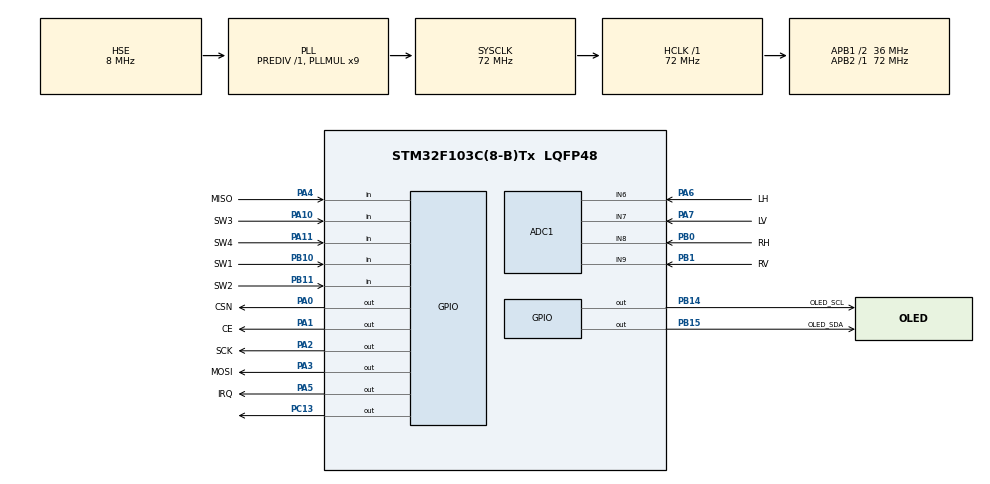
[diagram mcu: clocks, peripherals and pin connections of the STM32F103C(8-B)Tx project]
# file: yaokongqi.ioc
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ADC1.Channel-0\#ChannelRegularConversion=ADC_CHANNEL_6
ADC1.NbrOfConversionFlag=1
ADC1.Rank-0\#ChannelRegularConversion=1
ADC1.SamplingTime-0\#ChannelRegularConversion=ADC_SAMPLETIME_1CYCLE_5
ADC1.master=1
FREERTOS.Tasks01=defaultTask,24,128,StartDefaultTask,Default,NULL,Dynamic,NULL,NULL
FREERTOS.configTOTAL_HEAP_SIZE=8000
Mcu.Family=STM32F1
Mcu.Name=STM32F103C(8-B)Tx
Mcu.Package=LQFP48
NVIC.PriorityGroup=NVIC_PRIORITYGROUP_4
NVIC.TIM3_IRQn=true\:15\:0\:false\:false\:true\:false\:false\:true\:true
NVIC.TimeBase=TIM3_IRQn
NVIC.TimeBaseIP=TIM3
PA0-WKUP.GPIO_Label=CSN
PA0-WKUP.GPIO_PuPd=GPIO_NOPULL
PA0-WKUP.PinState=GPIO_PIN_SET
PA0-WKUP.Signal=GPIO_Output
PA1.GPIO_Label=CE
PA1.Signal=GPIO_Output
PA10.GPIO_Label=SW3
PA10.Signal=GPIO_Input
PA11.GPIO_Label=SW4
PA11.Signal=GPIO_Input
PA13.Mode=Serial_Wire
PA13.Signal=SYS_JTMS-SWDIO
PA14.Mode=Serial_Wire
PA14.Signal=SYS_JTCK-SWCLK
PA2.GPIO_Label=SCK
PA2.Signal=GPIO_Output
PA3.GPIO_Label=MOSI
PA3.Signal=GPIO_Output
PA4.GPIO_Label=MISO
PA4.GPIO_PuPd=GPIO_PULLUP
PA4.Signal=GPIO_Input
PA5.GPIO_Label=IRQ
PA5.Signal=GPIO_Output
PA6.GPIO_Label=LH
PA6.Signal=ADCx_IN6
PA7.GPIO_Label=LV
PA7.Signal=ADCx_IN7
PB0.GPIO_Label=RH
PB0.Signal=ADCx_IN8
PB1.GPIO_Label=RV
PB1.Signal=ADCx_IN9
PB10.GPIO_Label=SW1
PB10.Signal=GPIO_Input
PB11.GPIO_Label=SW2
PB11.Signal=GPIO_Input
PB14.GPIO_Label=OLED_SCL
PB14.Signal=GPIO_Output
PB15.GPIO_Label=OLED_SDA
PB15.Signal=GPIO_Output
PC13-TAMPER-RTC.Signal=GPIO_Output
PD0-OSC_IN.Mode=HSE-External-Oscillator
PD0-OSC_IN.Signal=RCC_OSC_IN
PD1-OSC_OUT.Mode=HSE-External-Oscillator
PD1-OSC_OUT.Signal=RCC_OSC_OUT
ProjectManager.HeapSize=0x200
ProjectManager.StackSize=0x400
ProjectManager.TargetToolchain=MDK-ARM V5.32
RCC.ADCPresc=RCC_ADCPCLK2_DIV6
RCC.AHBFreq_Value=72000000
RCC.APB1CLKDivider=RCC_HCLK_DIV2
RCC.APB1Freq_Value=36000000
RCC.APB1TimFreq_Value=72000000
RCC.APB2Freq_Value=72000000
RCC.APB2TimFreq_Value=72000000
RCC.HCLKFreq_Value=72000000
RCC.PLLMUL=RCC_PLL_MUL9
RCC.PLLSourceVirtual=RCC_PLLSOURCE_HSE
RCC.SYSCLKFreq_VALUE=72000000
RCC.SYSCLKSource=RCC_SYSCLKSOURCE_PLLCLK
RCC.USBFreq_Value=72000000
SH.ADCx_IN6.0=ADC1_IN6,IN6
SH.ADCx_IN7.0=ADC1_IN7,IN7
SH.ADCx_IN8.0=ADC1_IN8,IN8
SH.ADCx_IN9.0=ADC1_IN9,IN9
VP_FREERTOS_VS_CMSIS_V2.Mode=CMSIS_V2
VP_SYS_VS_tim3.Mode=TIM3
board=custom

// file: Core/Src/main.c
/* USER CODE BEGIN Header */
/**
  ******************************************************************************
  * @file           : main.c
  * @brief          : Main program body
  ******************************************************************************
  * @attention
  *
  * Copyright (c) 2026 STMicroelectronics.
  * All rights reserved.
  *
  * This software is licensed under terms that can be found in the LICENSE file
  * in the root directory of this software component.
  * If no LICENSE file comes with this software, it is provided AS-IS.
  *
  ******************************************************************************
  */
/* USER CODE END Header */
#include "main.h"
#include "cmsis_os.h"
#include "adc.h"
#include "gpio.h"

void SystemClock_Config(void);
void MX_FREERTOS_Init(void);

int main(void)
{

  /* MCU Configuration--------------------------------------------------------*/

  /* Reset of all peripherals, Initializes the Flash interface and the Systick. */
  HAL_Init();

  /* Configure the system clock */
  SystemClock_Config();

  /* Initialize all configured peripherals */
  MX_GPIO_Init();
  MX_ADC1_Init();

  /* Init scheduler */
  osKernelInitialize();

  /* Call init function for freertos objects (in cmsis_os2.c) */
  MX_FREERTOS_Init();

  /* Start scheduler */
  osKernelStart();

  /* We should never get here as control is now taken by the scheduler */

  /* Infinite loop */
  while (1)
  {

  }
}

void SystemClock_Config(void)
{
  RCC_OscInitTypeDef RCC_OscInitStruct = {0};
  RCC_ClkInitTypeDef RCC_ClkInitStruct = {0};
  RCC_PeriphCLKInitTypeDef PeriphClkInit = {0};

  /** Initializes the RCC Oscillators according to the specified parameters
  * in the RCC_OscInitTypeDef structure.
  */
  RCC_OscInitStruct.OscillatorType = RCC_OSCILLATORTYPE_HSE;
  RCC_OscInitStruct.HSEState = RCC_HSE_ON;
  RCC_OscInitStruct.HSEPredivValue = RCC_HSE_PREDIV_DIV1;
  RCC_OscInitStruct.HSIState = RCC_HSI_ON;
  RCC_OscInitStruct.PLL.PLLState = RCC_PLL_ON;
  RCC_OscInitStruct.PLL.PLLSource = RCC_PLLSOURCE_HSE;
  RCC_OscInitStruct.PLL.PLLMUL = RCC_PLL_MUL9;
  if (HAL_RCC_OscConfig(&RCC_OscInitStruct) != HAL_OK)
  {
    Error_Handler();
  }

  /** Initializes the CPU, AHB and APB buses clocks
  */
  RCC_ClkInitStruct.ClockType = RCC_CLOCKTYPE_HCLK|RCC_CLOCKTYPE_SYSCLK
                              |RCC_CLOCKTYPE_PCLK1|RCC_CLOCKTYPE_PCLK2;
  RCC_ClkInitStruct.SYSCLKSource = RCC_SYSCLKSOURCE_PLLCLK;
  RCC_ClkInitStruct.AHBCLKDivider = RCC_SYSCLK_DIV1;
  RCC_ClkInitStruct.APB1CLKDivider = RCC_HCLK_DIV2;
  RCC_ClkInitStruct.APB2CLKDivider = RCC_HCLK_DIV1;

  if (HAL_RCC_ClockConfig(&RCC_ClkInitStruct, FLASH_LATENCY_2) != HAL_OK)
  {
    Error_Handler();
  }
  PeriphClkInit.PeriphClockSelection = RCC_PERIPHCLK_ADC;
  PeriphClkInit.AdcClockSelection = RCC_ADCPCLK2_DIV6;
  if (HAL_RCCEx_PeriphCLKConfig(&PeriphClkInit) != HAL_OK)
  {
    Error_Handler();
  }
}

void HAL_TIM_PeriodElapsedCallback(TIM_HandleTypeDef *htim)
{
  if (htim->Instance == TIM3) {
    HAL_IncTick();
  }
}

void Error_Handler(void)
{
  __disable_irq();
  while (1)
  {
  }
}

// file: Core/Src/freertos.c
/* USER CODE BEGIN Header */
/**
  ******************************************************************************
  * File Name          : freertos.c
  * Description        : Code for freertos applications
  ******************************************************************************
  * @attention
  *
  * Copyright (c) 2026 STMicroelectronics.
  * All rights reserved.
  *
  * This software is licensed under terms that can be found in the LICENSE file
  * in the root directory of this software component.
  * If no LICENSE file comes with this software, it is provided AS-IS.
  *
  ******************************************************************************
  */
/* USER CODE END Header */

#include "FreeRTOS.h"
#include "task.h"
#include "main.h"
#include "cmsis_os.h"

/* USER CODE BEGIN Includes */
#include "bspsystem.h"
/* USER CODE END Includes */

/* Definitions for defaultTask */
osThreadId_t defaultTaskHandle;
const osThreadAttr_t defaultTask_attributes = {
  .name = "defaultTask",
  .stack_size = 128 * 4,
  .priority = (osPriority_t) osPriorityNormal,
};

void StartDefaultTask(void *argument);

void MX_FREERTOS_Init(void); /* (MISRA C 2004 rule 8.1) */

void MX_FREERTOS_Init(void) {

  /* Create the thread(s) */
  /* creation of defaultTask */
  defaultTaskHandle = osThreadNew(StartDefaultTask, NULL, &defaultTask_attributes);

  /* USER CODE BEGIN RTOS_THREADS */
  /* add threads, ... */
  xTaskCreate(oled_ShowTask, "oled_ShowTask", 128, NULL, osPriorityNormal, NULL);
  /* USER CODE END RTOS_THREADS */

}

void StartDefaultTask(void *argument)
{
  /* USER CODE BEGIN StartDefaultTask */
  /* Infinite loop */
  for(;;)
  {
    HAL_GPIO_TogglePin(GPIOC, GPIO_PIN_13);
    osDelay(500);
  }
  /* USER CODE END StartDefaultTask */
}
